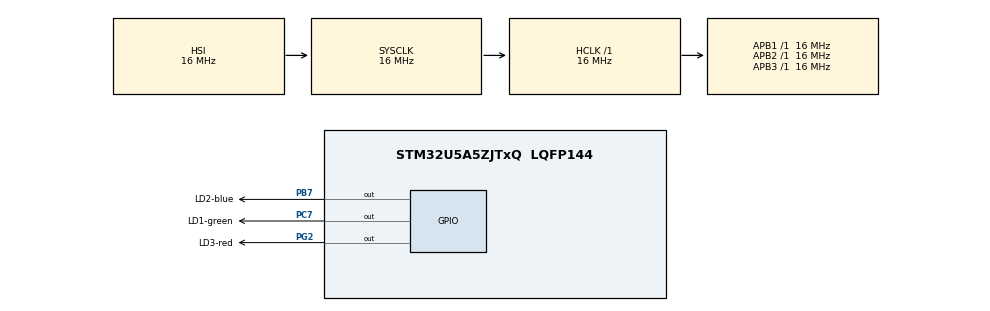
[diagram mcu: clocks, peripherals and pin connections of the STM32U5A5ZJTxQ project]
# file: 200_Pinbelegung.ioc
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CORTEX_M33_NS.AccessPermission-Cortex_Memory_Protection_Unit_Region0_Settings=MPU_REGION_PRIV_RO
CORTEX_M33_NS.AllocateAttribute0=MPU_R_ALLOCATE
CORTEX_M33_NS.AllocateAttribute1=MPU_RW_ALLOCATE
CORTEX_M33_NS.Attributes0=MPU_ATTRIBUTES_NUMBER0
CORTEX_M33_NS.Attributes1=MPU_ATTRIBUTES_NUMBER1
CORTEX_M33_NS.AttributesIndex-Cortex_Memory_Protection_Unit_Region1_Settings=MPU_ATTRIBUTES_NUMBER1
CORTEX_M33_NS.BaseAddress-Cortex_Memory_Protection_Unit_Region0_Settings=0x08000000
CORTEX_M33_NS.BaseAddress-Cortex_Memory_Protection_Unit_Region1_Settings=0x20000000
CORTEX_M33_NS.CacheableAttribute1=MPU_WRITE_BACK
CORTEX_M33_NS.Enable-Cortex_Memory_Protection_Unit_Region0_Settings=MPU_REGION_ENABLE
CORTEX_M33_NS.Enable-Cortex_Memory_Protection_Unit_Region1_Settings=MPU_REGION_ENABLE
CORTEX_M33_NS.LimitAddress-Cortex_Memory_Protection_Unit_Region0_Settings=0x083FFFFF
CORTEX_M33_NS.LimitAddress-Cortex_Memory_Protection_Unit_Region1_Settings=0x2026FFFF
CORTEX_M33_NS.MPU_Control=MPU_PRIVILEGED_DEFAULT
CORTEX_M33_NS.Memorytype0=MPU_CACHEABLE
CORTEX_M33_NS.Memorytype1=MPU_CACHEABLE
CORTEX_M33_NS.Number-Cortex_Memory_Protection_Unit_Region0_Settings=MPU_REGION_NUMBER0
CORTEX_M33_NS.Number-Cortex_Memory_Protection_Unit_Region1_Settings=MPU_REGION_NUMBER1
CORTEX_M33_NS.userName=CORTEX_M33
FLASH.B1_BLOCK_active=true
FLASH.B1_endPage=255
FLASH.B2_BLOCK_active=true
FLASH.B2_Bank=FLASH_BANK_2
FLASH.B2_endPage=255
FLASH.OB_Boot_Configuration_active_NS0=true
FLASH.OB_NSBOOTADD0_Address=0x08000000
GTZC.MPCBB1_Area_Privilege_Size=0x000C0000
GTZC.MPCBB1_SecConfig_array=00000000\:00000000\:00000000\:00000000\:00000000\:00000000\:00000000\:00000000\:00000000\:00000000\:00000000\:00000000\:00000000\:00000000\:00000000\:00000000\:00000000\:00000000\:00000000\:00000000\:00000000\:00000000\:00000000\:00000000\:00000000\:00000000\:00000000\:00000000\:00000000\:00000000\:00000000\:00000000\:00000000\:00000000\:00000000\:00000000\:00000000\:00000000\:00000000\:00000000\:00000000\:00000000\:00000000\:00000000\:00000000\:00000000\:00000000\:00000000
GTZC.MPCBB2_Area_Privilege_Size=0x00010000
GTZC.MPCBB2_PrivConfig_array=FFFFFFFF\:FFFFFFFF\:FFFFFFFF\:FFFFFFFF\:00000000\:00000000\:00000000\:00000000\:00000000\:00000000\:00000000\:00000000\:00000000\:00000000\:00000000\:00000000\:00000000\:00000000\:00000000\:00000000\:00000000\:00000000\:00000000\:00000000\:00000000\:00000000\:00000000\:00000000\:00000000\:00000000\:00000000\:00000000\:00000000\:00000000\:00000000\:00000000\:00000000\:00000000\:00000000\:00000000\:00000000\:00000000\:00000000\:00000000\:00000000\:00000000\:00000000\:00000000\:00000000\:00000000\:00000000\:00000000
GTZC.MPCBB2_SecConfig_array=00000000\:00000000\:00000000\:00000000\:00000000\:00000000\:00000000\:00000000\:00000000\:00000000\:00000000\:00000000\:00000000\:00000000\:00000000\:00000000\:00000000\:00000000\:00000000\:00000000\:00000000\:00000000\:00000000\:00000000\:00000000\:00000000\:00000000\:00000000\:00000000\:00000000\:00000000\:00000000\:00000000\:00000000\:00000000\:00000000\:00000000\:00000000\:00000000\:00000000\:00000000\:00000000\:00000000\:00000000\:00000000\:00000000\:00000000\:00000000\:00000000\:00000000\:00000000\:00000000
GTZC.MPCBB3_Area_Privilege_Size=0x000D0000
GTZC.MPCBB3_SecConfig_array=00000000\:00000000\:00000000\:00000000\:00000000\:00000000\:00000000\:00000000\:00000000\:00000000\:00000000\:00000000\:00000000\:00000000\:00000000\:00000000\:00000000\:00000000\:00000000\:00000000\:00000000\:00000000\:00000000\:00000000\:00000000\:00000000\:00000000\:00000000\:00000000\:00000000\:00000000\:00000000\:00000000\:00000000\:00000000\:00000000\:00000000\:00000000\:00000000\:00000000\:00000000\:00000000\:00000000\:00000000\:00000000\:00000000\:00000000\:00000000\:00000000\:00000000\:00000000\:00000000
GTZC.MPCBB4_PrivConfig_array=00000000
GTZC.MPCBB4_SecConfig_array=00000000
GTZC.MPCBB5_Area_Privilege_Size=0x000D0000
GTZC.MPCBB5_SecConfig_array=00000000\:00000000\:00000000\:00000000\:00000000\:00000000\:00000000\:00000000\:00000000\:00000000\:00000000\:00000000\:00000000\:00000000\:00000000\:00000000\:00000000\:00000000\:00000000\:00000000\:00000000\:00000000\:00000000\:00000000\:00000000\:00000000\:00000000\:00000000\:00000000\:00000000\:00000000\:00000000\:00000000\:00000000\:00000000\:00000000\:00000000\:00000000\:00000000\:00000000\:00000000\:00000000\:00000000\:00000000\:00000000\:00000000\:00000000\:00000000\:00000000\:00000000\:00000000\:00000000
Mcu.Family=STM32U5
Mcu.Name=STM32U5A5ZJTxQ
Mcu.Package=LQFP144
NVIC.PriorityGroup=NVIC_PRIORITYGROUP_4
PA13\ (JTMS/SWDIO).Mode=Trace_Asynchronous_SW
PA13\ (JTMS/SWDIO).Signal=DEBUG_JTMS-SWDIO
PA14\ (JTCK/SWCLK).Mode=Trace_Asynchronous_SW
PA14\ (JTCK/SWCLK).Signal=DEBUG_JTCK-SWCLK
PB3\ (JTDO/TRACESWO).Mode=Trace_Asynchronous_SW
PB3\ (JTDO/TRACESWO).Signal=DEBUG_JTDO-SWO
PB7.GPIO_Label=LD2-blue
PB7.Signal=GPIO_Output
PC14-OSC32_IN\ (PC14).Mode=LSE-External-Oscillator
PC14-OSC32_IN\ (PC14).Signal=RCC_OSC32_IN
PC15-OSC32_OUT\ (PC15).Mode=LSE-External-Oscillator
PC15-OSC32_OUT\ (PC15).Signal=RCC_OSC32_OUT
PC7.GPIO_Label=LD1-green
PC7.Signal=GPIO_Output
PG2.GPIO_Label=LD3-red
PG2.Signal=GPIO_Output
PWR.PowerMode=PWR_SMPS_SUPPLY
ProjectManager.HeapSize=0x2000
ProjectManager.StackSize=0x10000
ProjectManager.TargetToolchain=STM32CubeIDE
RCC.ADCFreq_Value=16000000
RCC.AHBFreq_Value=16000000
RCC.APB1Freq_Value=16000000
RCC.APB1TimFreq_Value=16000000
RCC.APB2Freq_Value=16000000
RCC.APB2TimFreq_Value=16000000
RCC.APB3Freq_Value=16000000
RCC.CortexFreq_Value=16000000
RCC.DACCLockSelectionVirtual=RCC_DAC1CLKSOURCE_LSI
RCC.EPOD_VALUE=16000000
RCC.HCLKFreq_Value=16000000
RCC.HSE_VALUE=16000000
RCC.HSI48_VALUE=48000000
RCC.HSI_VALUE=16000000
RCC.LSIDIV_VALUE=32000
RCC.MSIClockRange=RCC_MSIRANGE_0
RCC.MSI_VALUE=48000000
RCC.PLLFRACN=0
RCC.PLLN=20
RCC.PLLSourceVirtual=RCC_PLLSOURCE_HSI
RCC.SYSCLKFreq_VALUE=16000000
RCC.SYSCLKSource=RCC_SYSCLKSOURCE_HSI
RCC.USBPHYCLockSelection=RCC_USBPHYCLKSOURCE_HSE
RCC.VCOOutputFreq_Value=320000000
STMicroelectronics.X-CUBE-ALGOBUILD.1.4.0.LibraryCcDSPOoLibraryJjDSPOoLibrary=true
VP_FLASH_SIG_Activate_FlashIP.Mode=Activate_FlashIP
VP_GTZC_VS_GTZC_Enable.Mode=GTZC_Enable
VP_ICACHE_VS_ICACHE.Mode=DirectMappedCache
VP_LPBAMQUEUE_VS_QUEUE.Mode=QUEUEMODE
VP_MEMORYMAP_VS_MEMORYMAP.Mode=CurAppReg
VP_PWR_VS_DBSignals.Mode=DisableDeadBatterySignals
VP_PWR_VS_LPOM.Mode=PowerOptimisation
VP_PWR_VS_SECSignals.Mode=Security/Privilege
VP_STMicroelectronics.X-CUBE-ALGOBUILD_VS_DSPOoLibraryJjLibrary_1.4.0_1.4.0.Mode=DSPOoLibraryJjLibrary
board=NUCLEO-U5A5ZJ-Q

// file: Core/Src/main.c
/* USER CODE BEGIN Header */
/**
  ******************************************************************************
  * @file           : main.c
  * @brief          : Main program body
  ******************************************************************************
  * @attention
  *
  * Copyright (c) 2026 STMicroelectronics.
  * All rights reserved.
  *
  * This software is licensed under terms that can be found in the LICENSE file
  * in the root directory of this software component.
  * If no LICENSE file comes with this software, it is provided AS-IS.
  *
  ******************************************************************************
  */
/* USER CODE END Header */
#include "main.h"
#include "flash.h"
#include "gtzc.h"
#include "icache.h"
#include "gpio.h"

/* USER CODE BEGIN Includes */
// FFT
#include <stdio.h>
#include <stdlib.h>
#include "input.h"
#include <math.h>
#include "arm_math.h"
/* USER CODE END Includes */

/* USER CODE BEGIN PD */
#define N 8192	// Muss 2^N sein!
/* USER CODE END PD */

/* USER CODE BEGIN PV */
// Globale Variablen
float x[N];
float y[N];
float y_abs[N/2];
arm_rfft_fast_instance_f32 fft;
/* USER CODE END PV */

void SystemClock_Config(void);
static void SystemPower_Config(void);
static void MPU_Config(void);

int main(void)
{

  /* MCU Configuration--------------------------------------------------------*/

  /* MPU Configuration--------------------------------------------------------*/
  MPU_Config();

  /* Reset of all peripherals, Initializes the Flash interface and the Systick. */
  HAL_Init();

  /* Configure the System Power */
  SystemPower_Config();

  /* Configure the system clock */
  SystemClock_Config();
  /* GTZC initialisation */
  MX_GTZC_Init();

  /* Initialize all configured peripherals */
  MX_GPIO_Init();
  MX_ICACHE_Init();
  MX_FLASH_Init();
  /* USER CODE BEGIN 2 */
  arm_rfft_fast_init_f32(&fft, N);
  /* USER CODE END 2 */

  /* Infinite loop */
  /* USER CODE BEGIN WHILE */
  while (1)
  {
	  // Grüne LED
	  HAL_GPIO_TogglePin(LD1_green_GPIO_Port, LD1_green_Pin);

	  // FFT
	  arm_rfft_fast_f32(&fft, x, y, 0);

	  // Betrag
	  arm_cmplx_mag_f32(y, y_abs, N/2);

	  // Delay
	  HAL_Delay(200);

    /* USER CODE END WHILE */

  }
}

void SystemClock_Config(void)
{
  RCC_OscInitTypeDef RCC_OscInitStruct = {0};
  RCC_ClkInitTypeDef RCC_ClkInitStruct = {0};

  /** Configure the main internal regulator output voltage
  */
  if (HAL_PWREx_ControlVoltageScaling(PWR_REGULATOR_VOLTAGE_SCALE4) != HAL_OK)
  {
    Error_Handler();
  }

  /** Initializes the CPU, AHB and APB buses clocks
  */
  RCC_OscInitStruct.OscillatorType = RCC_OSCILLATORTYPE_HSI;
  RCC_OscInitStruct.HSIState = RCC_HSI_ON;
  RCC_OscInitStruct.HSICalibrationValue = RCC_HSICALIBRATION_DEFAULT;
  RCC_OscInitStruct.PLL.PLLState = RCC_PLL_NONE;
  if (HAL_RCC_OscConfig(&RCC_OscInitStruct) != HAL_OK)
  {
    Error_Handler();
  }

  /** Initializes the CPU, AHB and APB buses clocks
  */
  RCC_ClkInitStruct.ClockType = RCC_CLOCKTYPE_HCLK|RCC_CLOCKTYPE_SYSCLK
                              |RCC_CLOCKTYPE_PCLK1|RCC_CLOCKTYPE_PCLK2
                              |RCC_CLOCKTYPE_PCLK3;
  RCC_ClkInitStruct.SYSCLKSource = RCC_SYSCLKSOURCE_HSI;
  RCC_ClkInitStruct.AHBCLKDivider = RCC_SYSCLK_DIV1;
  RCC_ClkInitStruct.APB1CLKDivider = RCC_HCLK_DIV1;
  RCC_ClkInitStruct.APB2CLKDivider = RCC_HCLK_DIV1;
  RCC_ClkInitStruct.APB3CLKDivider = RCC_HCLK_DIV1;

  if (HAL_RCC_ClockConfig(&RCC_ClkInitStruct, FLASH_LATENCY_1) != HAL_OK)
  {
    Error_Handler();
  }
}

/**
  * @brief Power Configuration
  * @retval None
  */
static void SystemPower_Config(void)
{
  HAL_PWREx_EnableVddIO2();

  /*
   * Disable the internal Pull-Up in Dead Battery pins of UCPD peripheral
   */
  HAL_PWREx_DisableUCPDDeadBattery();

  /*
   * Switch to SMPS regulator instead of LDO
   */
  if (HAL_PWREx_ConfigSupply(PWR_SMPS_SUPPLY) != HAL_OK)
  {
    Error_Handler();
  }
}

 /* MPU Configuration */

void MPU_Config(void)
{
  MPU_Region_InitTypeDef MPU_InitStruct = {0};
  MPU_Attributes_InitTypeDef MPU_AttributesInit = {0};

  /* Disables the MPU */
  HAL_MPU_Disable();

  /** Initializes and configures the Region 0 and the memory to be protected
  */
  MPU_InitStruct.Enable = MPU_REGION_ENABLE;
  MPU_InitStruct.Number = MPU_REGION_NUMBER0;
  MPU_InitStruct.BaseAddress = 0x08000000;
  MPU_InitStruct.LimitAddress = 0x083FFFFF;
  MPU_InitStruct.AttributesIndex = MPU_ATTRIBUTES_NUMBER0;
  MPU_InitStruct.AccessPermission = MPU_REGION_PRIV_RO;
  MPU_InitStruct.DisableExec = MPU_INSTRUCTION_ACCESS_ENABLE;
  MPU_InitStruct.IsShareable = MPU_ACCESS_NOT_SHAREABLE;

  HAL_MPU_ConfigRegion(&MPU_InitStruct);

  /** Initializes and configures the Region 1 and the memory to be protected
  */
  MPU_InitStruct.Number = MPU_REGION_NUMBER1;
  MPU_InitStruct.BaseAddress = 0x20000000;
  MPU_InitStruct.LimitAddress = 0x2026FFFF;
  MPU_InitStruct.AttributesIndex = MPU_ATTRIBUTES_NUMBER1;
  MPU_InitStruct.AccessPermission = MPU_REGION_PRIV_RW;

  HAL_MPU_ConfigRegion(&MPU_InitStruct);

  /** Initializes and configures the Attribute 0 and the memory to be protected
  */
  MPU_AttributesInit.Number = MPU_ATTRIBUTES_NUMBER0;
  MPU_AttributesInit.Attributes = INNER_OUTER(MPU_WRITE_THROUGH|MPU_TRANSIENT
                              |MPU_R_ALLOCATE);

  HAL_MPU_ConfigMemoryAttributes(&MPU_AttributesInit);

  /** Initializes and configures the Attribute 1 and the memory to be protected
  */
  MPU_AttributesInit.Number = MPU_ATTRIBUTES_NUMBER1;
  MPU_AttributesInit.Attributes = INNER_OUTER(MPU_WRITE_BACK|MPU_TRANSIENT
                              |MPU_RW_ALLOCATE);

  HAL_MPU_ConfigMemoryAttributes(&MPU_AttributesInit);
  /* Enables the MPU */
  HAL_MPU_Enable(MPU_PRIVILEGED_DEFAULT);

}

void Error_Handler(void)
{
  __disable_irq();
  while (1)
  {
  }
}
